# ioat91sam3s2 register map
Registers are 32-bit, access not given, no defined reset value unless marked. A register's access mark holds for its fields unless they carry their own. Addresses are absolute; registers are grouped by the start of their names; [hi:lo] are bit positions; {n}, {i} and the like mark numbered series; 'fields as' and 'values as' point back to an identical list.

## UART0
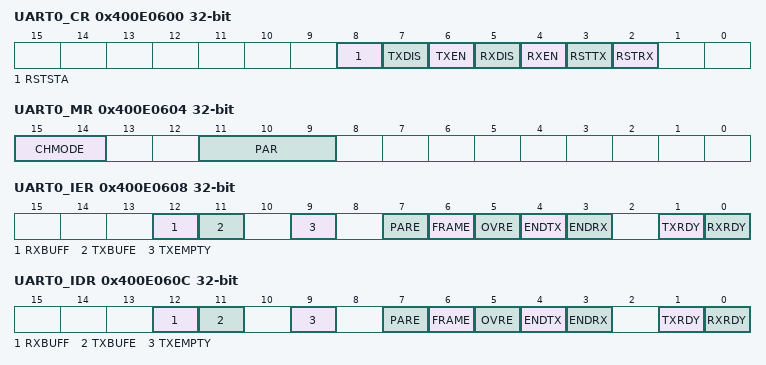
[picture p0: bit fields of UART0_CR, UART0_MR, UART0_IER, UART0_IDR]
0x400E0600 UART0_CR
  [8] RSTSTA, [7] TXDIS, [6] TXEN, [5] RXDIS, [4] RXEN, [3] RSTTX, [2] RSTRX
0x400E0604 UART0_MR
  [15:14] CHMODE, [11:9] PAR
0x400E0608 UART0_IER
  [12] RXBUFF, [11] TXBUFE, [9] TXEMPTY, [7] PARE, [6] FRAME, [5] OVRE, [4] ENDTX, [3] ENDRX, [1] TXRDY, [0] RXRDY
0x400E060C UART0_IDR
  fields as UART0_IER
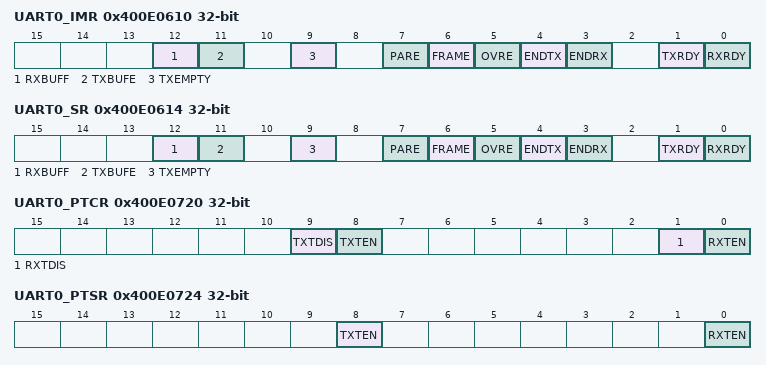
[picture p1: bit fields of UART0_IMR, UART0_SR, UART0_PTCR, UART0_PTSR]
0x400E0610 UART0_IMR
  fields as UART0_IER
0x400E0614 UART0_SR
  fields as UART0_IER
0x400E0618 UART0_RHR
  [7:0] RXCHR
0x400E061C UART0_THR
  [7:0] TXCHR
0x400E0620 UART0_BRGR
  [15:0] CD
0x400E0700 UART0_RPR
  [31:0] RXPTR
0x400E0704 UART0_RCR
  [15:0] RXCTR
0x400E0708 UART0_TPR
  [31:0] TXPTR
0x400E070C UART0_TCR
  [15:0] TXCTR
0x400E0710 UART0_RNPR
  [31:0] RXNPTR
0x400E0714 UART0_RNCR
  [15:0] RXNCTR
0x400E0718 UART0_TNPR
  [31:0] TXNPTR
0x400E071C UART0_TNCR
  [15:0] TXNCTR
0x400E0720 UART0_PTCR
  [9] TXTDIS, [8] TXTEN, [1] RXTDIS, [0] RXTEN
0x400E0724 UART0_PTSR
  [8] TXTEN, [0] RXTEN

## CHIPID
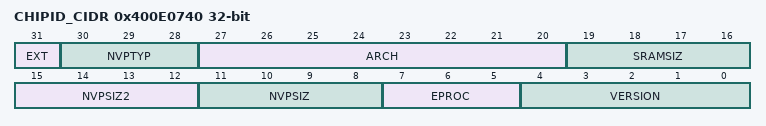
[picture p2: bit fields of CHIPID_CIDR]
0x400E0740 CHIPID_CIDR
  [31] EXT, [30:28] NVPTYP, [27:20] ARCH, [19:16] SRAMSIZ, [15:12] NVPSIZ2, [11:8] NVPSIZ, [7:5] EPROC, [4:0] VERSION
0x400E0744 CHIPID_EXID

## UART1
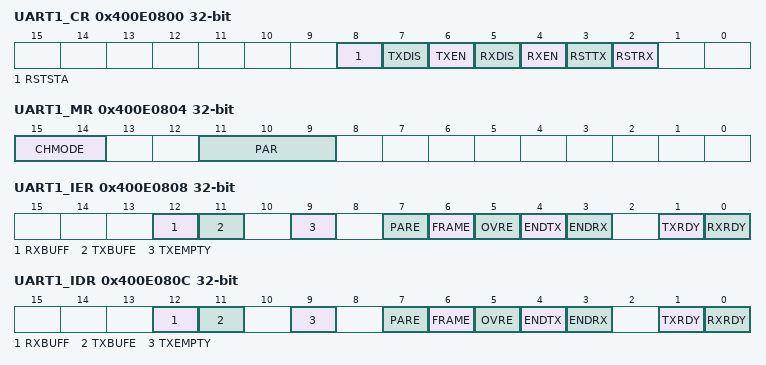
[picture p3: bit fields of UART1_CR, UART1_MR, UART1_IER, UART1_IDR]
0x400E0800 UART1_CR
  [8] RSTSTA, [7] TXDIS, [6] TXEN, [5] RXDIS, [4] RXEN, [3] RSTTX, [2] RSTRX
0x400E0804 UART1_MR
  [15:14] CHMODE, [11:9] PAR
0x400E0808 UART1_IER
  [12] RXBUFF, [11] TXBUFE, [9] TXEMPTY, [7] PARE, [6] FRAME, [5] OVRE, [4] ENDTX, [3] ENDRX, [1] TXRDY, [0] RXRDY
0x400E080C UART1_IDR
  fields as UART1_IER
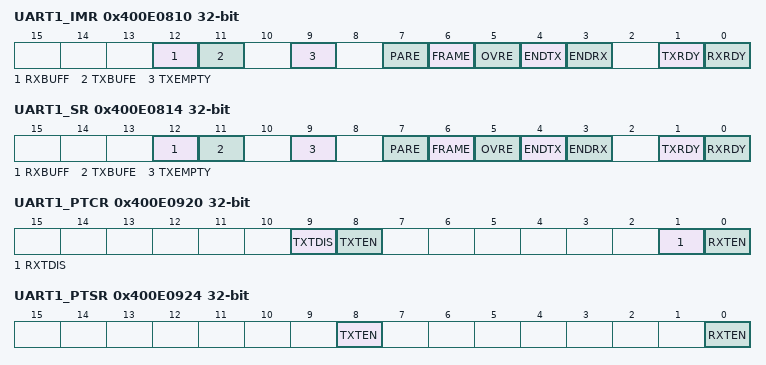
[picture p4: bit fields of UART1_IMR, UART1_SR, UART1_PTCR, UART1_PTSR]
0x400E0810 UART1_IMR
  fields as UART1_IER
0x400E0814 UART1_SR
  fields as UART1_IER
0x400E0818 UART1_RHR
  [7:0] RXCHR
0x400E081C UART1_THR
  [7:0] TXCHR
0x400E0820 UART1_BRGR
  [15:0] CD
0x400E0900 UART1_RPR
  [31:0] RXPTR
0x400E0904 UART1_RCR
  [15:0] RXCTR
0x400E0908 UART1_TPR
  [31:0] TXPTR
0x400E090C UART1_TCR
  [15:0] TXCTR
0x400E0910 UART1_RNPR
  [31:0] RXNPTR
0x400E0914 UART1_RNCR
  [15:0] RXNCTR
0x400E0918 UART1_TNPR
  [31:0] TXNPTR
0x400E091C UART1_TNCR
  [15:0] TXNCTR
0x400E0920 UART1_PTCR
  [9] TXTDIS, [8] TXTEN, [1] RXTDIS, [0] RXTEN
0x400E0924 UART1_PTSR
  [8] TXTEN, [0] RXTEN

## EFC
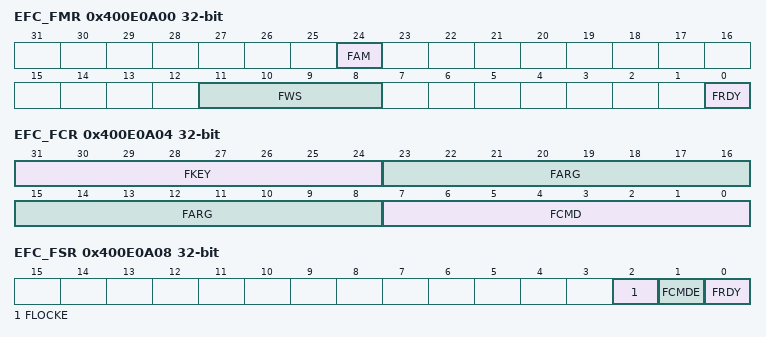
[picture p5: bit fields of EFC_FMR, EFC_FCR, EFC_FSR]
0x400E0A00 EFC_FMR
  [24] FAM, [11:8] FWS, [0] FRDY
0x400E0A04 EFC_FCR
  [31:24] FKEY, [23:8] FARG, [7:0] FCMD
0x400E0A08 EFC_FSR
  [2] FLOCKE, [1] FCMDE, [0] FRDY
0x400E0A0C EFC_FRR
  [31:0] FVALUE

## PIOA
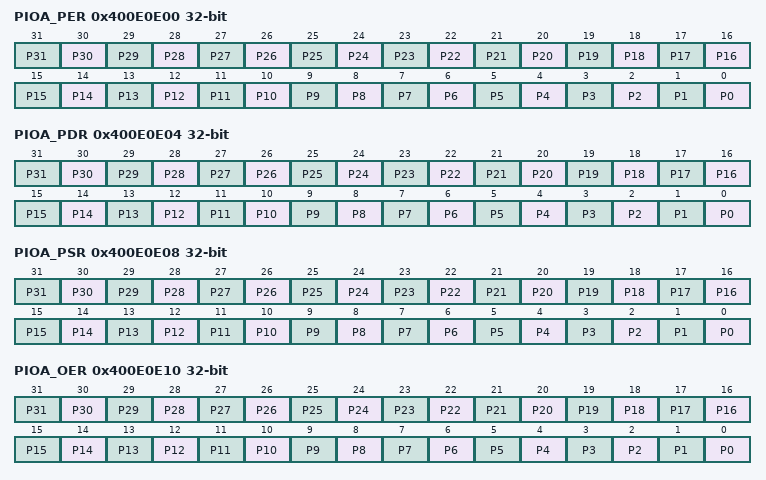
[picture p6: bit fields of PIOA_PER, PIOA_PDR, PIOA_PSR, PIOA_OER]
0x400E0E00 PIOA_PER
  [n] P{n} (n=0..31)
0x400E0E04 PIOA_PDR
  [n] P{n} (n=0..31)
0x400E0E08 PIOA_PSR
  [n] P{n} (n=0..31)
0x400E0E10 PIOA_OER
  [n] P{n} (n=0..31)
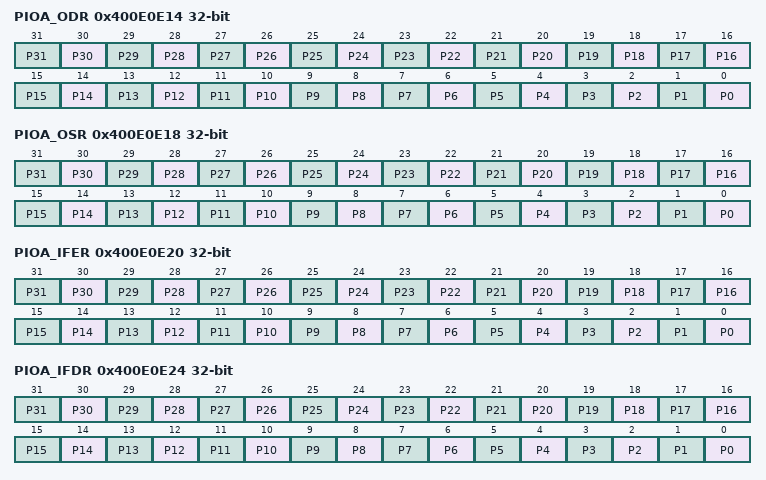
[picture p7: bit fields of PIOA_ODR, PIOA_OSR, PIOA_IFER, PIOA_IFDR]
0x400E0E14 PIOA_ODR
  [n] P{n} (n=0..31)
0x400E0E18 PIOA_OSR
  [n] P{n} (n=0..31)
0x400E0E20 PIOA_IFER
  [n] P{n} (n=0..31)
0x400E0E24 PIOA_IFDR
  [n] P{n} (n=0..31)
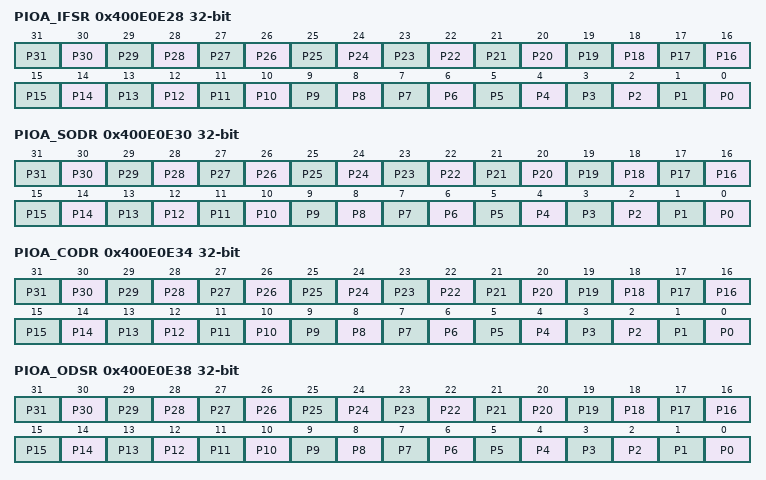
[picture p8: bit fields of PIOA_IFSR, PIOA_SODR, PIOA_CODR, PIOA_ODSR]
0x400E0E28 PIOA_IFSR
  [n] P{n} (n=0..31)
0x400E0E30 PIOA_SODR
  [n] P{n} (n=0..31)
0x400E0E34 PIOA_CODR
  [n] P{n} (n=0..31)
0x400E0E38 PIOA_ODSR
  [n] P{n} (n=0..31)
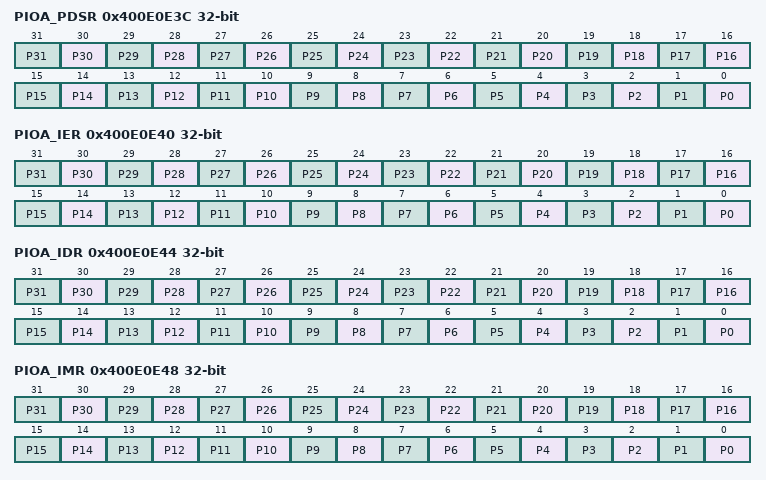
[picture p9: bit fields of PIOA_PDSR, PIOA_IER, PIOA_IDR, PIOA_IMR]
0x400E0E3C PIOA_PDSR
  [n] P{n} (n=0..31)
0x400E0E40 PIOA_IER
  [n] P{n} (n=0..31)
0x400E0E44 PIOA_IDR
  [n] P{n} (n=0..31)
0x400E0E48 PIOA_IMR
  [n] P{n} (n=0..31)
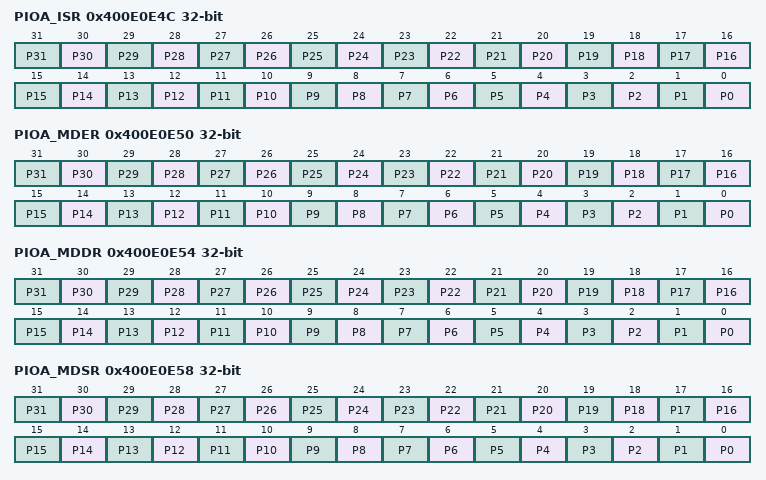
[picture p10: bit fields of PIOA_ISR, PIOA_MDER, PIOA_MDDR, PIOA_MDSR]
0x400E0E4C PIOA_ISR
  [n] P{n} (n=0..31)
0x400E0E50 PIOA_MDER
  [n] P{n} (n=0..31)
0x400E0E54 PIOA_MDDR
  [n] P{n} (n=0..31)
0x400E0E58 PIOA_MDSR
  [n] P{n} (n=0..31)
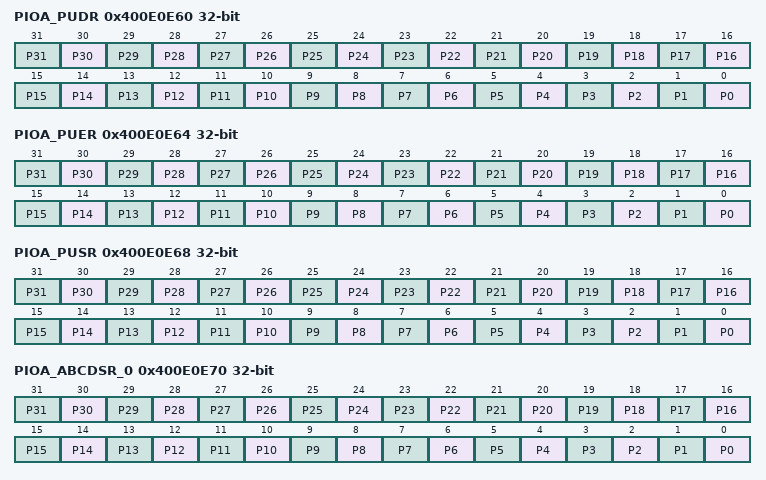
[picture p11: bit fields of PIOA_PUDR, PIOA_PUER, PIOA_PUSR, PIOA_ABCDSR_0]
0x400E0E60 PIOA_PUDR
  [n] P{n} (n=0..31)
0x400E0E64 PIOA_PUER
  [n] P{n} (n=0..31)
0x400E0E68 PIOA_PUSR
  [n] P{n} (n=0..31)
0x400E0E70 PIOA_ABCDSR_0
  [n] P{n} (n=0..31)
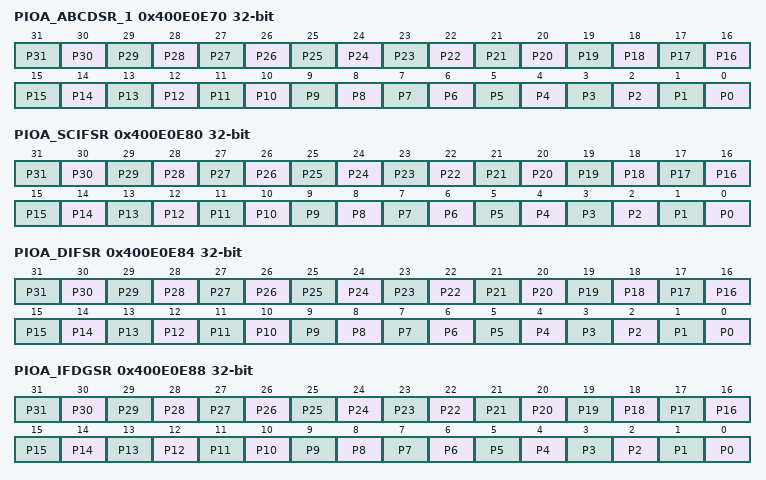
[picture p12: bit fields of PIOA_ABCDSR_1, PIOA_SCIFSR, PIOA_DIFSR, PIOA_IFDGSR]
0x400E0E70 PIOA_ABCDSR_1
  [n] P{n} (n=0..31)
0x400E0E80 PIOA_SCIFSR
  [n] P{n} (n=0..31)
0x400E0E84 PIOA_DIFSR
  [n] P{n} (n=0..31)
0x400E0E88 PIOA_IFDGSR
  [n] P{n} (n=0..31)
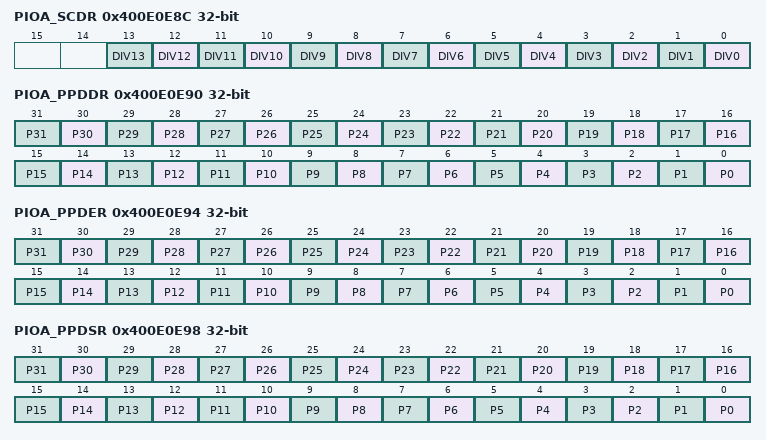
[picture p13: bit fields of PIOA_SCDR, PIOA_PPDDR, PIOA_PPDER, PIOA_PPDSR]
0x400E0E8C PIOA_SCDR
  [n] DIV{n} (n=0..13)
0x400E0E90 PIOA_PPDDR
  [n] P{n} (n=0..31)
0x400E0E94 PIOA_PPDER
  [n] P{n} (n=0..31)
0x400E0E98 PIOA_PPDSR
  [n] P{n} (n=0..31)
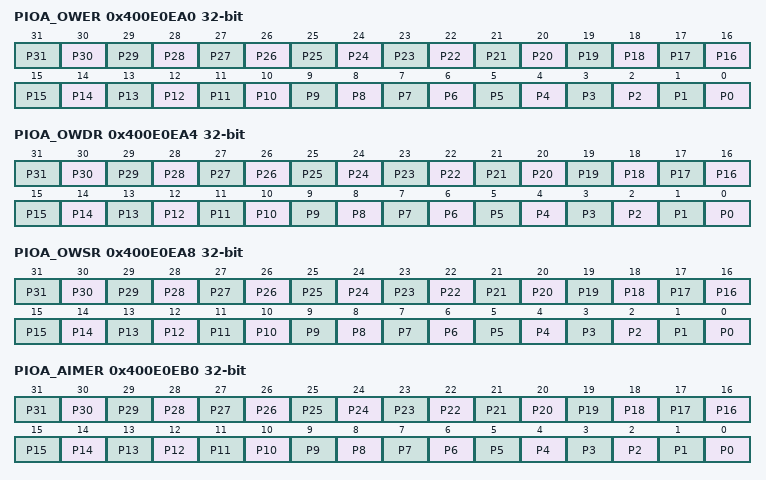
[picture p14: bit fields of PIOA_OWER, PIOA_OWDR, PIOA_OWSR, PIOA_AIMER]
0x400E0EA0 PIOA_OWER
  [n] P{n} (n=0..31)
0x400E0EA4 PIOA_OWDR
  [n] P{n} (n=0..31)
0x400E0EA8 PIOA_OWSR
  [n] P{n} (n=0..31)
0x400E0EB0 PIOA_AIMER
  [n] P{n} (n=0..31)
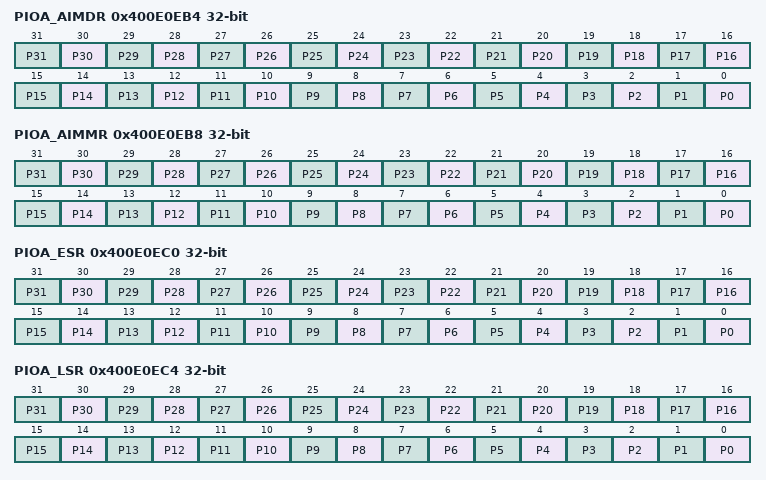
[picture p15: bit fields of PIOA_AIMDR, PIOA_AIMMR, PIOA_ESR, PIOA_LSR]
0x400E0EB4 PIOA_AIMDR
  [n] P{n} (n=0..31)
0x400E0EB8 PIOA_AIMMR
  [n] P{n} (n=0..31)
0x400E0EC0 PIOA_ESR
  [n] P{n} (n=0..31)
0x400E0EC4 PIOA_LSR
  [n] P{n} (n=0..31)
0x400E0EC8 PIOA_ELSR
  [n] P{n} (n=0..31)
0x400E0ED0 PIOA_FELLSR
  [n] P{n} (n=0..31)
0x400E0ED4 PIOA_REHLSR
  [n] P{n} (n=0..31)
0x400E0ED8 PIOA_FRLHSR
  [n] P{n} (n=0..31)
0x400E0EE0 PIOA_LOCKSR
  [n] P{n} (n=0..31)
0x400E0EE4 PIOA_WPMR
  [31:8] WPKEY, [0] WPEN
0x400E0EE8 PIOA_WPSR
  [23:8] WPVSRC, [0] WPVS
0x400E0F00 PIOA_SCHMITT
  [n] SCHMITT{n} (n=0..31)
0x400E0F50 PIOA_PCMR
  [11] FRSTS, [10] HALFS, [9] ALWYS, [5:4] DSIZE, [0] PCEN
0x400E0F54 PIOA_PCIER
  [3] RXBUFF, [2] ENDRX, [1] OVRE, [0] DRDY
0x400E0F58 PIOA_PCIDR
  [3] RXBUFF, [2] ENDRX, [1] OVRE, [0] DRDY
0x400E0F5C PIOA_PCIMR
  [3] RXBUFF, [2] ENDRX, [1] OVRE, [0] DRDY
0x400E0F60 PIOA_PCISR
  [3] RXBUFF, [2] ENDRX, [1] OVRE, [0] DRDY
0x400E0F64 PIOA_PCRHR
  [31:0] RDATA
